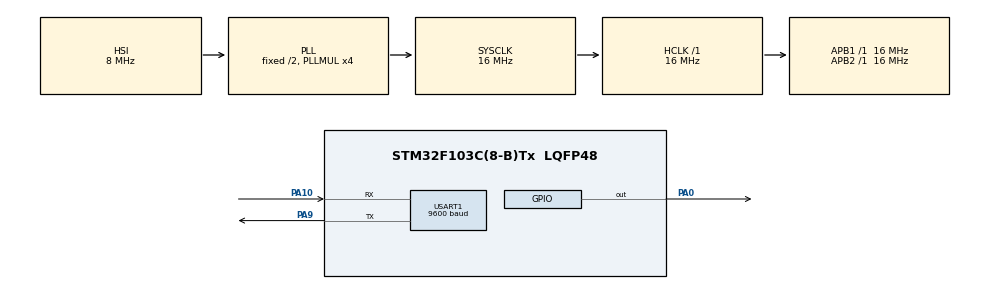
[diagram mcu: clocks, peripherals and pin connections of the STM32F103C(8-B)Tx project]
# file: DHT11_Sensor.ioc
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Mcu.Family=STM32F1
Mcu.Name=STM32F103C(8-B)Tx
Mcu.Package=LQFP48
NVIC.PriorityGroup=NVIC_PRIORITYGROUP_4
PA0-WKUP.Signal=GPIO_Output
PA10.Mode=Asynchronous
PA10.Signal=USART1_RX
PA9.Mode=Asynchronous
PA9.Signal=USART1_TX
ProjectManager.HeapSize=0x200
ProjectManager.StackSize=0x400
ProjectManager.TargetToolchain=STM32CubeIDE
RCC.AHBFreq_Value=16000000
RCC.APB1Freq_Value=16000000
RCC.APB1TimFreq_Value=16000000
RCC.APB2Freq_Value=16000000
RCC.APB2TimFreq_Value=16000000
RCC.HCLKFreq_Value=16000000
RCC.PLLMUL=RCC_PLL_MUL4
RCC.SYSCLKFreq_VALUE=16000000
RCC.SYSCLKSource=RCC_SYSCLKSOURCE_PLLCLK
RCC.USBFreq_Value=16000000
TIM1.Prescaler=15
USART1.BaudRate=9600
USART1.VirtualMode=VM_ASYNC
VP_SYS_VS_ND.Mode=No_Debug
VP_TIM1_VS_ClockSourceINT.Mode=Internal
board=custom

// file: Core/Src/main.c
/* USER CODE BEGIN Header */
/**
  ******************************************************************************
  * @file           : main.c
  * @brief          : Main program body
  ******************************************************************************
  * @attention
  *
  * Copyright (c) 2024 STMicroelectronics.
  * All rights reserved.
  *
  * This software is licensed under terms that can be found in the LICENSE file
  * in the root directory of this software component.
  * If no LICENSE file comes with this software, it is provided AS-IS.
  *
  ******************************************************************************
  */
/* USER CODE END Header */
#include "main.h"

/* USER CODE BEGIN Includes */
#include<string.h>
#include<stdio.h>
/* USER CODE END Includes */

/* USER CODE BEGIN PD */
#define DHT11_Pin GPIO_PIN_0
#define DHT11_GPIO_Port GPIOA
/* USER CODE END PD */

TIM_HandleTypeDef htim1;

UART_HandleTypeDef huart1;

/* USER CODE BEGIN PV */

char msg[50] ;
char message1[16];
char message1[16];
uint8_t TOUT =0 , CheckSum , i;
uint8_t T_Byte1 , T_Byte2 , RH_Byte1 , RH_Byte2 ;

/* USER CODE END PV */

void SystemClock_Config(void);
static void MX_GPIO_Init(void);
static void MX_TIM1_Init(void);
static void MX_USART1_UART_Init(void);

/* USER CODE BEGIN 0 */

/********************************** DHT11 ********************/

void delay_us ( uint16_t us)
{
    __HAL_TIM_SET_COUNTER(&htim1,0);
    while(__HAL_TIM_GET_COUNTER(&htim1) < us);
}

void start_signal (void){
     GPIO_InitTypeDef GPIO_InitStruct = {0};

      GPIO_InitStruct.Pin = DHT11_Pin;
      GPIO_InitStruct.Mode = GPIO_MODE_OUTPUT_PP;
      GPIO_InitStruct.Pull = GPIO_NOPULL;
      GPIO_InitStruct.Speed = GPIO_SPEED_FREQ_LOW;
      HAL_GPIO_Init(DHT11_GPIO_Port, &GPIO_InitStruct);

      HAL_GPIO_WritePin(DHT11_GPIO_Port, DHT11_Pin, GPIO_PIN_RESET);
      HAL_Delay(18);
      HAL_GPIO_WritePin(DHT11_GPIO_Port, DHT11_Pin, GPIO_PIN_SET);
      delay_us(30);

      GPIO_InitStruct.Mode = GPIO_MODE_INPUT;
      HAL_GPIO_Init(DHT11_GPIO_Port, &GPIO_InitStruct);

}

uint8_t check_response(void){
    TOUT=0;
    __HAL_TIM_SET_COUNTER(&htim1,0);
    while(!HAL_GPIO_ReadPin(DHT11_GPIO_Port, DHT11_Pin) && (__HAL_TIM_GET_COUNTER(&htim1) < 100)) {};
    if(__HAL_TIM_GET_COUNTER(&htim1)>= 100){
        return 0; //timeout
    }
    while(HAL_GPIO_ReadPin(DHT11_GPIO_Port, DHT11_Pin) && (__HAL_TIM_GET_COUNTER(&htim1) < 100)) {};
        if(__HAL_TIM_GET_COUNTER(&htim1)>= 100){
            return 0; //timeout
        }
    return 1;
}

uint8_t read_byte(void){
    uint8_t num =0 ;
    for(i=0 ;i<8; i++){
        while(!HAL_GPIO_ReadPin(DHT11_GPIO_Port, DHT11_Pin))  {};
        __HAL_TIM_SET_COUNTER(&htim1,0);
        while(HAL_GPIO_ReadPin(DHT11_GPIO_Port, DHT11_Pin))  {};
        if(__HAL_TIM_GET_COUNTER(&htim1) > 40)
        {
            num |= (1 << (7 - i));
        }

    }
    return num;
}

void process_sensor_data(void){
    RH_Byte1 = read_byte();
    RH_Byte2 = read_byte();
    T_Byte1 = read_byte();
    T_Byte2 = read_byte();
    CheckSum = read_byte();

    uint8_t humidity_integer =  RH_Byte1 ;
    uint8_t humidity_decimal =  RH_Byte2 / 10 ;

    uint8_t temperature_integer =  T_Byte1 ;
    uint8_t temperature_decimal =  T_Byte2 / 10 ;

    if(CheckSum ==((RH_Byte1+RH_Byte2 +T_Byte1+T_Byte2)& 0xff)){
        snprintf(msg,sizeof(msg),"RH = %d.%d %%\r\n",humidity_integer,humidity_decimal);
        send_uart_message(msg);
        snprintf(msg,sizeof(msg),"temp = %d.%d C\r\n",temperature_integer,temperature_decimal);
        send_uart_message(msg);

    }else
    {
        send_uart_message("Checksum Errors ! Trying Again ...\r\n");
    }
}

void send_uart_message(char *messsage){
    HAL_UART_Transmit(&huart1, (uint8_t*)messsage, strlen(messsage), HAL_MAX_DELAY);
}

/*************************************** DHT11 ************************************/

/* USER CODE END 0 */

int main(void)
{

  /* MCU Configuration--------------------------------------------------------*/

  /* Reset of all peripherals, Initializes the Flash interface and the Systick. */
  HAL_Init();

  /* Configure the system clock */
  SystemClock_Config();

  /* Initialize all configured peripherals */
  MX_GPIO_Init();
  MX_TIM1_Init();
  MX_USART1_UART_Init();
  /* USER CODE BEGIN 2 */
  HAL_TIM_Base_Start(&htim1);
  send_uart_message("Initilization Complet \n\r");
  /* USER CODE END 2 */

  /* Infinite loop */
  while (1)
  {

      HAL_Delay(2000); // 1 second delay before starting
      start_signal();
      uint8_t check = check_response();
      if (!check){
          send_uart_message("No responce from the sensor \r\n");
      } else {
          process_sensor_data();
      }

  }
}

void SystemClock_Config(void)
{
  RCC_OscInitTypeDef RCC_OscInitStruct = {0};
  RCC_ClkInitTypeDef RCC_ClkInitStruct = {0};

  /** Initializes the RCC Oscillators according to the specified parameters
  * in the RCC_OscInitTypeDef structure.
  */
  RCC_OscInitStruct.OscillatorType = RCC_OSCILLATORTYPE_HSI;
  RCC_OscInitStruct.HSIState = RCC_HSI_ON;
  RCC_OscInitStruct.HSICalibrationValue = RCC_HSICALIBRATION_DEFAULT;
  RCC_OscInitStruct.PLL.PLLState = RCC_PLL_ON;
  RCC_OscInitStruct.PLL.PLLSource = RCC_PLLSOURCE_HSI_DIV2;
  RCC_OscInitStruct.PLL.PLLMUL = RCC_PLL_MUL4;
  if (HAL_RCC_OscConfig(&RCC_OscInitStruct) != HAL_OK)
  {
    Error_Handler();
  }

  /** Initializes the CPU, AHB and APB buses clocks
  */
  RCC_ClkInitStruct.ClockType = RCC_CLOCKTYPE_HCLK|RCC_CLOCKTYPE_SYSCLK
                              |RCC_CLOCKTYPE_PCLK1|RCC_CLOCKTYPE_PCLK2;
  RCC_ClkInitStruct.SYSCLKSource = RCC_SYSCLKSOURCE_PLLCLK;
  RCC_ClkInitStruct.AHBCLKDivider = RCC_SYSCLK_DIV1;
  RCC_ClkInitStruct.APB1CLKDivider = RCC_HCLK_DIV1;
  RCC_ClkInitStruct.APB2CLKDivider = RCC_HCLK_DIV1;

  if (HAL_RCC_ClockConfig(&RCC_ClkInitStruct, FLASH_LATENCY_0) != HAL_OK)
  {
    Error_Handler();
  }
}

static void MX_TIM1_Init(void)
{

  TIM_ClockConfigTypeDef sClockSourceConfig = {0};
  TIM_MasterConfigTypeDef sMasterConfig = {0};

  htim1.Instance = TIM1;
  htim1.Init.Prescaler = 15;
  htim1.Init.CounterMode = TIM_COUNTERMODE_UP;
  htim1.Init.Period = 65535;
  htim1.Init.ClockDivision = TIM_CLOCKDIVISION_DIV1;
  htim1.Init.RepetitionCounter = 0;
  htim1.Init.AutoReloadPreload = TIM_AUTORELOAD_PRELOAD_DISABLE;
  if (HAL_TIM_Base_Init(&htim1) != HAL_OK)
  {
    Error_Handler();
  }
  sClockSourceConfig.ClockSource = TIM_CLOCKSOURCE_INTERNAL;
  if (HAL_TIM_ConfigClockSource(&htim1, &sClockSourceConfig) != HAL_OK)
  {
    Error_Handler();
  }
  sMasterConfig.MasterOutputTrigger = TIM_TRGO_RESET;
  sMasterConfig.MasterSlaveMode = TIM_MASTERSLAVEMODE_DISABLE;
  if (HAL_TIMEx_MasterConfigSynchronization(&htim1, &sMasterConfig) != HAL_OK)
  {
    Error_Handler();
  }

}

static void MX_USART1_UART_Init(void)
{

  huart1.Instance = USART1;
  huart1.Init.BaudRate = 9600;
  huart1.Init.WordLength = UART_WORDLENGTH_8B;
  huart1.Init.StopBits = UART_STOPBITS_1;
  huart1.Init.Parity = UART_PARITY_NONE;
  huart1.Init.Mode = UART_MODE_TX_RX;
  huart1.Init.HwFlowCtl = UART_HWCONTROL_NONE;
  huart1.Init.OverSampling = UART_OVERSAMPLING_16;
  if (HAL_UART_Init(&huart1) != HAL_OK)
  {
    Error_Handler();
  }

}

static void MX_GPIO_Init(void)
{
  GPIO_InitTypeDef GPIO_InitStruct = {0};

  /* GPIO Ports Clock Enable */
  __HAL_RCC_GPIOA_CLK_ENABLE();

  /*Configure GPIO pin Output Level */
  HAL_GPIO_WritePin(GPIOA, GPIO_PIN_0, GPIO_PIN_RESET);

  /*Configure GPIO pin : PA0 */
  GPIO_InitStruct.Pin = GPIO_PIN_0;
  GPIO_InitStruct.Mode = GPIO_MODE_OUTPUT_PP;
  GPIO_InitStruct.Pull = GPIO_NOPULL;
  GPIO_InitStruct.Speed = GPIO_SPEED_FREQ_LOW;
  HAL_GPIO_Init(GPIOA, &GPIO_InitStruct);

}

void Error_Handler(void)
{
  __disable_irq();
  while (1)
  {
  }
}
